# f1c100s register map
Vendor: Allwinner; File version: 1.0
Registers are 32-bit, read-write, reset 0x0 unless marked. A register's access mark holds for its fields unless they carry their own. Offsets are from the block's base; [hi:lo] are bit positions; {n}, {i} and the like mark numbered series; 'fields as' and 'values as' point back to an identical list.

## PIO — Port Controller (GPIO)
Base 0x01C20800
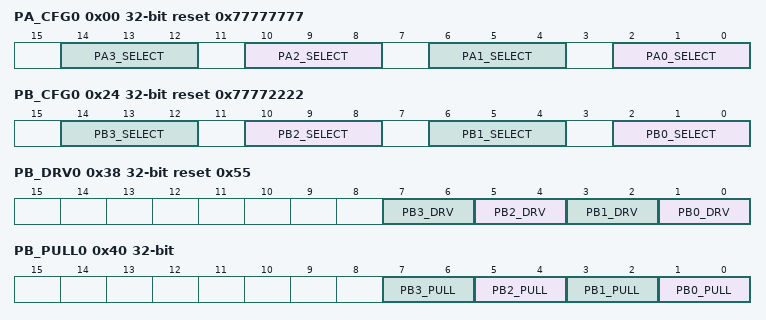
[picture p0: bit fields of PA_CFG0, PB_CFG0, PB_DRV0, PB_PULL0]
0x00 PA_CFG0 reset 0x77777777 — PA Configure Register 0
  [4n+2:4n] PA{n}_SELECT (n=0..3)
{0x0+4i} PA_CFG{i} (i=1..3) — PA Configure Register {i}
0x10 PA_DATA
  [3:0] PA_DAT — PA Data
0x14 PA_DRV0 — PA Multi-Driving Register 0
0x18 PA_DRV1 — PA Multi-Driving Register 1
0x1C PA_PULL0 — PA Pull Register 0
0x20 PA_PULL1 — PA Pull Register 1
0x24 PB_CFG0 reset 0x77772222 — PB Configure Register 0
  [4n+2:4n] PB{n}_SELECT (n=0..3)
0x28 PB_CFG1 — PB Configure Register 1
0x2C PB_CFG2 — PB Configure Register 2
0x30 PB_CFG3 reset 0x7 — PB Configure Register 3
0x34 PB_DATA
  [3:0] PB_DAT — PB Data
0x38 PB_DRV0 reset 0x55 — PB Multi-Driving Register 0
  [2n+1:2n] PB{n}_DRV (n=0..3) — PB{n} Multi-Driving Select
0x3C PB_DRV1 — PB Multi-Driving Register 1
0x40 PB_PULL0 — PB Pull Register 0
  [2n+1:2n] PB{n}_PULL (n=0..3) — PB{n} Pull Select
0x44 PB_PULL1 — PB Pull Register 1
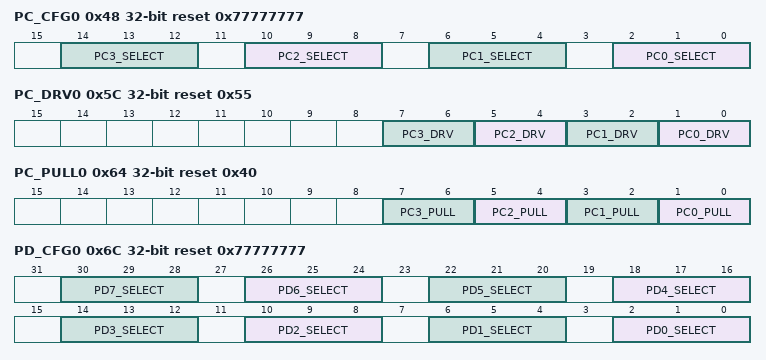
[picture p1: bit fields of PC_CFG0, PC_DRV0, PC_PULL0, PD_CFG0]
0x48 PC_CFG0 reset 0x77777777 — PC Configure Register 0
  [4n+2:4n] PC{n}_SELECT (n=0..3)
{0x48+4i} PC_CFG{i} (i=1..3) — PC Configure Register {i}
0x58 PC_DATA
  [3:0] PC_DAT — PC Data
0x5C PC_DRV0 reset 0x55 — PC Multi-Driving Register 0
  [2n+1:2n] PC{n}_DRV (n=0..3) — PC{n} Multi-Driving Select
0x60 PC_DRV1 — PC Multi-Driving Register 1
0x64 PC_PULL0 reset 0x40 — PC Pull Register 0
  [2n+1:2n] PC{n}_PULL (n=0..3) — PC{n} Pull Select
0x68 PC_PULL1 — PC Pull Register 1
0x6C PD_CFG0 reset 0x77777777 — PD Configure Register 0
  [4n+2:4n] PD{n}_SELECT (n=0..7)
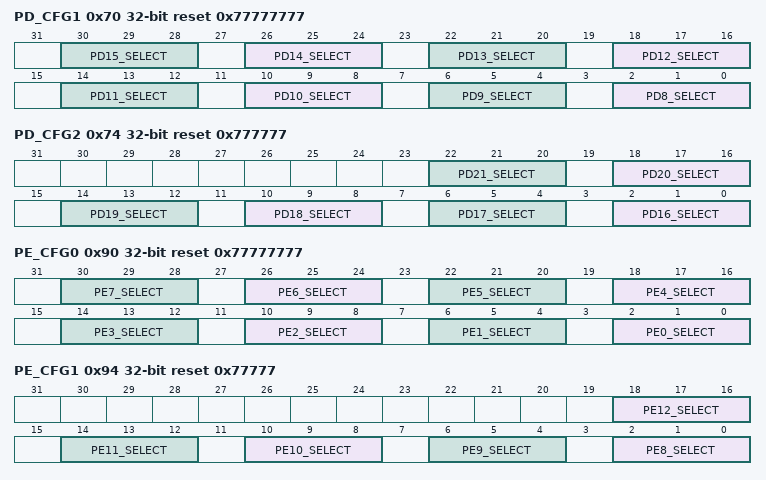
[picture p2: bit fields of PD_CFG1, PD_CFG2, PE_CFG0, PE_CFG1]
0x70 PD_CFG1 reset 0x77777777 — PD Configure Register 1
  [4n-30:4n-32] PD{n}_SELECT (n=8..15)
0x74 PD_CFG2 reset 0x777777 — PD Configure Register 2
  [4n-62:4n-64] PD{n}_SELECT (n=16..21)
0x78 PD_CFG3 — PD Configure Register 3
0x7C PD_DATA
  [21:0] PD_DAT — PD Data
0x80 PD_DRV0 reset 0x55555555 — PD Multi-Driving Register 0
  [31:0] PD_DRV — PD0-15 Multi-Driving Select
0x84 PD_DRV1 reset 0x555 — PD Multi-Driving Register 1
  [11:0] PD_DRV — PD16-21 Multi-Driving Select
0x88 PD_PULL0 — PD Pull Register 0
  [31:0] PD_PULL — PD0-15 Pull Select
0x8C PD_PULL1 — PD Pull Register 1
  [11:0] PD_PULL — PD16-21 Pull Select
0x90 PE_CFG0 reset 0x77777777 — PE Configure Register 0
  [4n+2:4n] PE{n}_SELECT (n=0..7)
0x94 PE_CFG1 reset 0x77777 — PE Configure Register 1
  [4n-30:4n-32] PE{n}_SELECT (n=8..12)
0x98 PE_CFG2 — PE Configure Register 2
0x9C PE_CFG3 — PE Configure Register 3
0xA0 PE_DATA
  [12:0] PE_DAT — PE Data
0xA4 PE_DRV0 reset 0x1555555 — PE Multi-Driving Register 0
  [25:0] PE_DRV — PE0-12 Multi-Driving Select
0xA8 PE_DRV1 — PE Multi-Driving Register 1
0xAC PE_PULL0 — PE Pull Register 0
  [25:0] PE_PULL — PE0-12 Pull Select
0xB0 PE_PULL1 — PE Pull Register 1
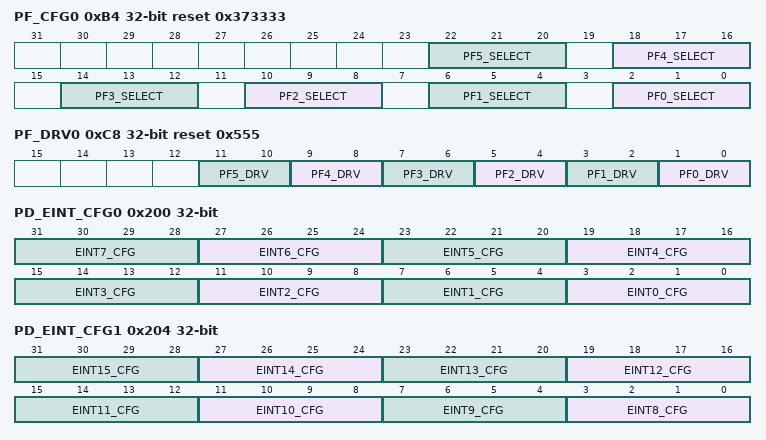
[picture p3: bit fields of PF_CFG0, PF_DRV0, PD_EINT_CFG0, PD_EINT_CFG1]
0xB4 PF_CFG0 reset 0x373333 — PF Configure Register 0
  [4n+2:4n] PF{n}_SELECT (n=0..5)
{0xB4+4i} PF_CFG{i} (i=1..3) — PF Configure Register {i}
0xC4 PF_DATA
  [5:0] PF_DAT — PF Data
0xC8 PF_DRV0 reset 0x555 — PF Multi-Driving Register 0
  [2n+1:2n] PF{n}_DRV (n=0..5) — PF{n} Multi-Driving Select
0xCC PF_DRV1 — PF Multi-Driving Register 1
0xD0 PF_PULL0 — PF Pull Register 0
0xD4 PF_PULL1 — PF Pull Register 1
0x200 PD_EINT_CFG0 — PD External Interrupt Configure Register 0
  [4n+3:4n] EINT{n}_CFG (n=0..7) — External INT{n} Mode
0x204 PD_EINT_CFG1 — PD External Interrupt Configure Register 1
  [4n-29:4n-32] EINT{n}_CFG (n=8..15) — External INT{n} Mode
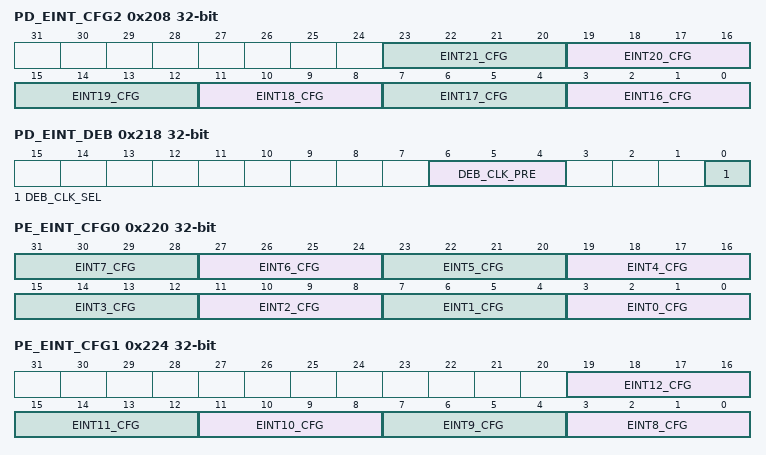
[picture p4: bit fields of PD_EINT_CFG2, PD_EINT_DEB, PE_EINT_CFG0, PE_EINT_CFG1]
0x208 PD_EINT_CFG2 — PD External Interrupt Configure Register 2
  [4n-61:4n-64] EINT{n}_CFG (n=16..21) — External INT{n} Mode
0x20C PD_EINT_CFG3 — PD External Interrupt Configure Register 3
0x210 PD_EINT_CTL — PD External Interrupt Control Register
  [21:0] EINT_CTL — External INT Enable (bit n for PD_EINTn)
0x214 PD_EINT_STA — PD External Interrupt Status Register
  [21:0] EINT_STA — External INT Pending (write 1 to clear)
0x218 PD_EINT_DEB — PD External Interrupt Debounce Register
  [6:4] DEB_CLK_PRE — Debounce Clock Prescale
  [0] DEB_CLK_SEL — Debounce Clock Select (0: LOSC, 1: HOSC)
0x220 PE_EINT_CFG0 — PE External Interrupt Configure Register 0
  [4n+3:4n] EINT{n}_CFG (n=0..7) — External INT{n} Mode
0x224 PE_EINT_CFG1 — PE External Interrupt Configure Register 1
  [4n-29:4n-32] EINT{n}_CFG (n=8..12) — External INT{n} Mode
0x228 PE_EINT_CFG2 — PE External Interrupt Configure Register 2
0x22C PE_EINT_CFG3 — PE External Interrupt Configure Register 3
0x230 PE_EINT_CTL — PE External Interrupt Control Register
  [12:0] EINT_CTL — External INT Enable (bit n for PE_EINTn)
0x234 PE_EINT_STA — PE External Interrupt Status Register
  [12:0] EINT_STA — External INT Pending (write 1 to clear)
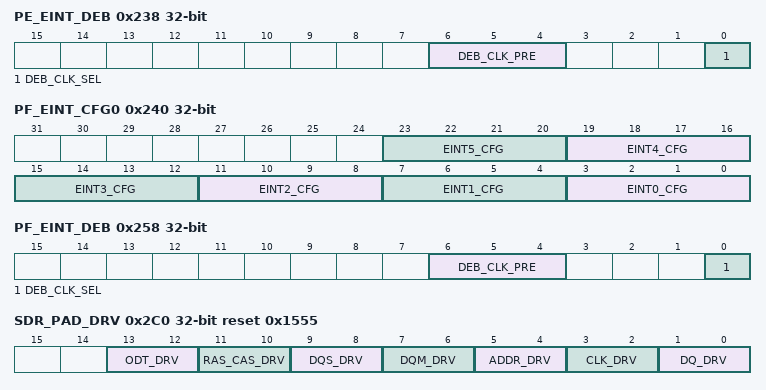
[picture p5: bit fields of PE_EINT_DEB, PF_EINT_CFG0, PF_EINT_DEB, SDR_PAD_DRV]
0x238 PE_EINT_DEB — PE External Interrupt Debounce Register
  fields as PD_EINT_DEB
0x240 PF_EINT_CFG0 — PF External Interrupt Configure Register 0
  [4n+3:4n] EINT{n}_CFG (n=0..5) — External INT{n} Mode
{0x240+4i} PF_EINT_CFG{i} (i=1..3) — PF External Interrupt Configure Register {i}
0x250 PF_EINT_CTL — PF External Interrupt Control Register
  [5:0] EINT_CTL — External INT Enable (bit n for PF_EINTn)
0x254 PF_EINT_STA — PF External Interrupt Status Register
  [5:0] EINT_STA — External INT Pending (write 1 to clear)
0x258 PF_EINT_DEB — PF External Interrupt Debounce Register
  fields as PD_EINT_DEB
0x2C0 SDR_PAD_DRV reset 0x1555 — SDRAM Pad Multi-Driving Register
  [13:12] ODT_DRV — ODT Multi-Driving Select
  [11:10] RAS_CAS_DRV — RAS#, CAS#, SWE#, SCS#, CKE Multi-Driving Select
  [9:8] DQS_DRV — DQS Multi-Driving Select
  [7:6] DQM_DRV — DQM Multi-Driving Select
  [5:4] ADDR_DRV — DA, BA Multi-Driving Select
  [3:2] CLK_DRV — CK, CK# Multi-Driving Select
  [1:0] DQ_DRV — DQ Multi-Driving Select
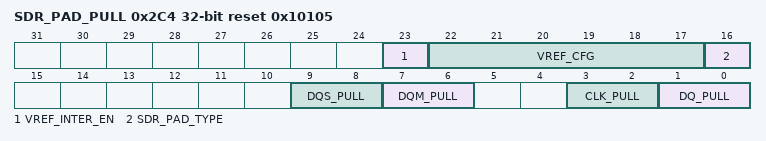
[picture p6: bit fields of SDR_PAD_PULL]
0x2C4 SDR_PAD_PULL reset 0x10105 — SDRAM Pad Pull Register
  [23] VREF_INTER_EN — Internal Reference Enable
  [22:17] VREF_CFG — Reference Configuration Factor
  [16] SDR_PAD_TYPE — SDRAM Pad Type (0: LVCMOS, 1: SSTL-2)
  [9:8] DQS_PULL — DQS Pull-up Select
  [7:6] DQM_PULL — DQM Pull-up Select
  [3:2] CLK_PULL — CK, CK# Pull-up Select
  [1:0] DQ_PULL — DQ Pull-up Select
